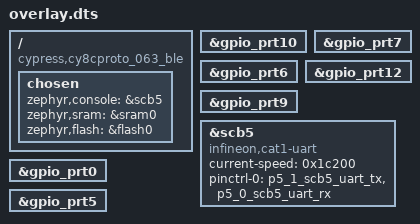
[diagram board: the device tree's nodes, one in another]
/ {
	compatible = "cypress,cy8cproto_063_ble", "cypress,PSoC6";
	chosen {
		zephyr,console = &scb5;
		zephyr,sram = &sram0;
		zephyr,flash = &flash0;
	};
};
&gpio_prt10{
	status = "okay";
};
&gpio_prt7{
	status = "okay";
};
&gpio_prt6{
	status = "okay";
};
&gpio_prt12{
	status = "okay";
};
&gpio_prt9{
	status = "okay";
};
&scb5{
	compatible = "infineon,cat1-uart";
	status = "okay";
	current-speed = < 0x1c200 >;
	pinctrl-0 = < &p5_1_scb5_uart_tx &p5_0_scb5_uart_rx >;
	pinctrl-names = "default";
};
&gpio_prt0{
	status = "okay";
};
&gpio_prt5{
	status = "okay";
};
